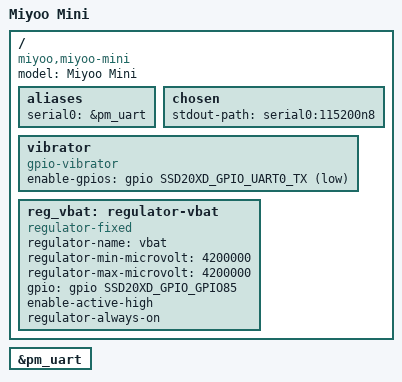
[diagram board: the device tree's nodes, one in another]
// SPDX-License-Identifier: GPL-2.0-or-later
/*
 * Copyright (c) 2021 thingy.jp.
 * Author: Daniel Palmer <daniel@thingy.jp>
 */

/dts-v1/;
#include "mstar-infinity2m-ssd202d.dtsi"

#include <dt-bindings/gpio/gpio.h>

/ {
	model = "Miyoo Mini";
	compatible = "miyoo,miyoo-mini", "mstar,infinity2m";

	aliases {
		serial0 = &pm_uart;
	};

	chosen {
		stdout-path = "serial0:115200n8";
	};

	vibrator {
		compatible = "gpio-vibrator";
		enable-gpios = <&gpio SSD20XD_GPIO_UART0_TX GPIO_ACTIVE_LOW>;
	};

	reg_vbat: regulator-vbat {
		compatible = "regulator-fixed";
		regulator-name = "vbat";
		regulator-min-microvolt = <4200000>;
		regulator-max-microvolt = <4200000>;
		gpio = <&gpio SSD20XD_GPIO_GPIO85 GPIO_ACTIVE_HIGH>;
		enable-active-high;
		regulator-always-on;
	};
};

&pm_uart {
	status = "okay";
};
